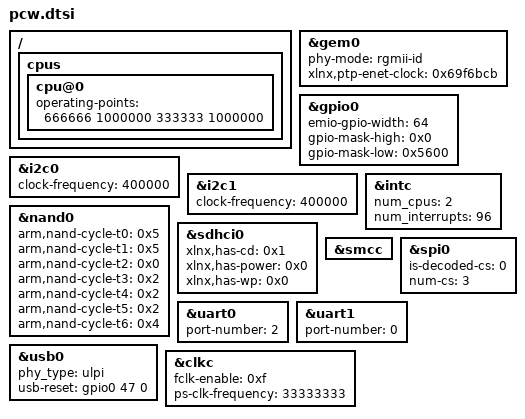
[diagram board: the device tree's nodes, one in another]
/*
 * CAUTION: This file is automatically generated by Xilinx.
 * Version:  
 * Today is: Sat Mar 30 14:48:00 2024
 */


/ {
	cpus {
		cpu@0 {
			operating-points = <666666 1000000 333333 1000000>;
		};
	};
};
&gem0 {
	phy-mode = "rgmii-id";
	status = "okay";
	xlnx,ptp-enet-clock = <0x69f6bcb>;
};
&gpio0 {
	emio-gpio-width = <64>;
	gpio-mask-high = <0x0>;
	gpio-mask-low = <0x5600>;
};
&i2c0 {
	clock-frequency = <400000>;
	status = "okay";
};
&i2c1 {
	clock-frequency = <400000>;
	status = "okay";
};
&intc {
	num_cpus = <2>;
	num_interrupts = <96>;
};
&nand0 {
	arm,nand-cycle-t0 = <0x5>;
	arm,nand-cycle-t1 = <0x5>;
	arm,nand-cycle-t2 = <0x0>;
	arm,nand-cycle-t3 = <0x2>;
	arm,nand-cycle-t4 = <0x2>;
	arm,nand-cycle-t5 = <0x2>;
	arm,nand-cycle-t6 = <0x4>;
	status = "okay";
};
&sdhci0 {
	status = "okay";
	xlnx,has-cd = <0x1>;
	xlnx,has-power = <0x0>;
	xlnx,has-wp = <0x0>;
};
&smcc {
	status = "okay";
};
&spi0 {
	is-decoded-cs = <0>;
	num-cs = <3>;
	status = "okay";
};
&uart0 {
	device_type = "serial";
	port-number = <2>;
	status = "okay";
};
&uart1 {
	device_type = "serial";
	port-number = <0>;
	status = "okay";
};
&usb0 {
	phy_type = "ulpi";
	status = "okay";
	usb-reset = <&gpio0 47 0>;
};
&clkc {
	fclk-enable = <0xf>;
	ps-clk-frequency = <33333333>;
};
